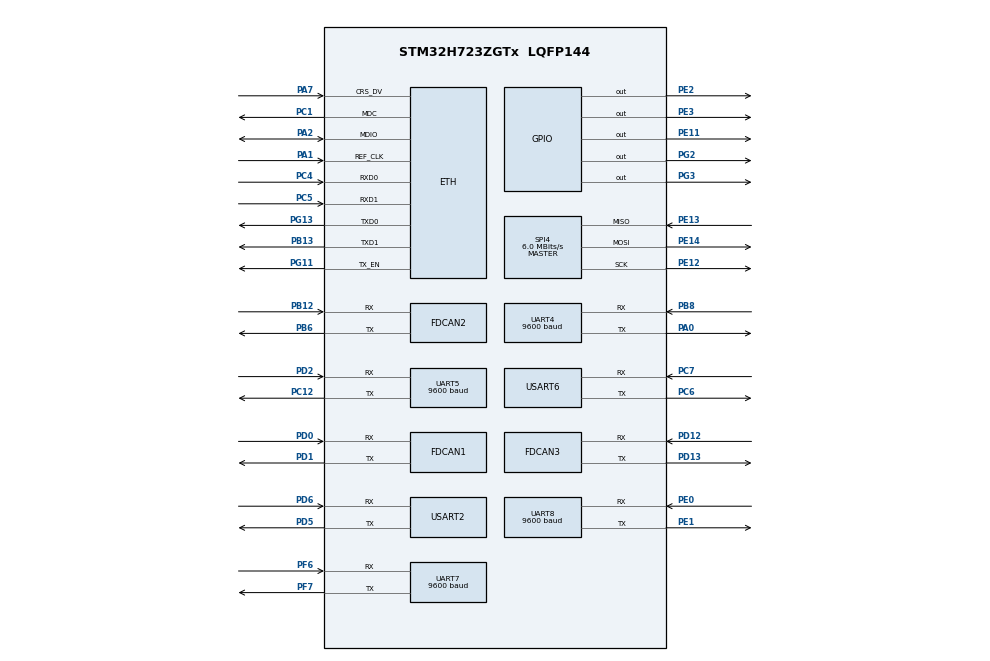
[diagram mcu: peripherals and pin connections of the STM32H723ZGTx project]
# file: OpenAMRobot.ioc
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CORTEX_M7.default_mode_Activation=1
ETH.MediaInterface=HAL_ETH_RMII_MODE
FDCAN1.AutoRetransmission=ENABLE
FDCAN1.CalculateBaudRateNominal=500000
FDCAN1.CalculateTimeBitNominal=2000
FDCAN1.CalculateTimeQuantumNominal=125.0
FDCAN1.NominalPrescaler=6
FDCAN1.NominalTimeSeg1=13
FDCAN1.NominalTimeSeg2=2
FDCAN1.RxFifo0ElmtsNbr=16
FDCAN1.StdFiltersNbr=1
FDCAN1.TxFifoQueueElmtsNbr=8
FDCAN2.AutoRetransmission=ENABLE
FDCAN2.CalculateBaudRateNominal=250000
FDCAN2.CalculateTimeBitNominal=4000
FDCAN2.CalculateTimeQuantumNominal=250.0
FDCAN2.MessageRAMOffset=256
FDCAN2.NominalPrescaler=12
FDCAN2.NominalTimeSeg1=13
FDCAN2.NominalTimeSeg2=2
FDCAN2.RxFifo0ElmtsNbr=16
FDCAN2.StdFiltersNbr=1
FDCAN2.TxFifoQueueElmtsNbr=8
FDCAN3.AutoRetransmission=ENABLE
FDCAN3.CalculateBaudRateNominal=500000
FDCAN3.CalculateTimeBitNominal=2000
FDCAN3.CalculateTimeQuantumNominal=125.0
FDCAN3.MessageRAMOffset=512
FDCAN3.NominalPrescaler=6
FDCAN3.NominalTimeSeg1=13
FDCAN3.NominalTimeSeg2=2
FDCAN3.RxFifo0ElmtsNbr=16
FDCAN3.StdFiltersNbr=1
FDCAN3.TxFifoQueueElmtsNbr=8
Mcu.Family=STM32H7
Mcu.Name=STM32H723ZGTx
Mcu.Package=LQFP144
NVIC.ETH_IRQn=true\:5\:0\:true\:false\:true\:true\:true\:true
NVIC.FDCAN1_IT0_IRQn=true\:5\:0\:true\:false\:true\:true\:true\:true
NVIC.FDCAN2_IT0_IRQn=true\:5\:0\:true\:false\:true\:true\:true\:true
NVIC.FDCAN3_IT0_IRQn=true\:5\:0\:true\:false\:true\:true\:true\:true
NVIC.PriorityGroup=NVIC_PRIORITYGROUP_4
NVIC.UART4_IRQn=true\:5\:0\:true\:false\:true\:true\:true\:true
NVIC.UART5_IRQn=true\:5\:0\:true\:false\:true\:true\:true\:true
NVIC.UART7_IRQn=true\:5\:0\:true\:false\:true\:true\:true\:true
NVIC.UART8_IRQn=true\:5\:0\:true\:false\:true\:true\:true\:true
NVIC.USART2_IRQn=true\:5\:0\:true\:false\:true\:true\:true\:true
NVIC.USART6_IRQn=true\:5\:0\:true\:false\:true\:true\:true\:true
PA0.Mode=Asynchronous
PA0.Signal=UART4_TX
PA1.Mode=RMII
PA1.Signal=ETH_REF_CLK
PA13(JTMS/SWDIO).GPIO_Label=SWDIO
PA13(JTMS/SWDIO).Mode=Serial_Wire
PA13(JTMS/SWDIO).Signal=DEBUG_JTMS-SWDIO
PA14(JTCK/SWCLK).GPIO_Label=SWCLK
PA14(JTCK/SWCLK).Mode=Serial_Wire
PA14(JTCK/SWCLK).Signal=DEBUG_JTCK-SWCLK
PA2.Mode=RMII
PA2.Signal=ETH_MDIO
PA7.Mode=RMII
PA7.Signal=ETH_CRS_DV
PB12.Mode=FDCAN_Activate
PB12.Signal=FDCAN2_RX
PB13.Mode=RMII
PB13.Signal=ETH_TXD1
PB6.Mode=FDCAN_Activate
PB6.Signal=FDCAN2_TX
PB8.Mode=Asynchronous
PB8.Signal=UART4_RX
PC1.Mode=RMII
PC1.Signal=ETH_MDC
PC12.Mode=Asynchronous
PC12.Signal=UART5_TX
PC14-OSC32_IN.Signal=RCC_OSC32_IN
PC15-OSC32_OUT.Signal=RCC_OSC32_OUT
PC4.Mode=RMII
PC4.Signal=ETH_RXD0
PC5.Mode=RMII
PC5.Signal=ETH_RXD1
PC6.Mode=Asynchronous
PC6.Signal=USART6_TX
PC7.Mode=Asynchronous
PC7.Signal=USART6_RX
PD0.Mode=FDCAN_Activate
PD0.Signal=FDCAN1_RX
PD1.Mode=FDCAN_Activate
PD1.Signal=FDCAN1_TX
PD12.Mode=FDCAN_Activate
PD12.Signal=FDCAN3_RX
PD13.Mode=FDCAN_Activate
PD13.Signal=FDCAN3_TX
PD2.Mode=Asynchronous
PD2.Signal=UART5_RX
PD5.Mode=Asynchronous
PD5.Signal=USART2_TX
PD6.Mode=Asynchronous
PD6.Signal=USART2_RX
PE0.Mode=Asynchronous
PE0.Signal=UART8_RX
PE1.Mode=Asynchronous
PE1.Signal=UART8_TX
PE11.PinState=GPIO_PIN_SET
PE11.Signal=GPIO_Output
PE12.Mode=Full_Duplex_Master
PE12.Signal=SPI4_SCK
PE13.GPIO_Mode=GPIO_MODE_AF_PP
PE13.GPIO_PuPd=GPIO_NOPULL
PE13.GPIO_Speed=GPIO_SPEED_FREQ_LOW
PE13.Mode=Full_Duplex_Master
PE13.Signal=SPI4_MISO
PE14.Mode=Full_Duplex_Master
PE14.Signal=SPI4_MOSI
PE2.Signal=GPIO_Output
PE3.Signal=GPIO_Output
PF6.Mode=Asynchronous
PF6.Signal=UART7_RX
PF7.Mode=Asynchronous
PF7.Signal=UART7_TX
PG11.Mode=RMII
PG11.Signal=ETH_TX_EN
PG13.Mode=RMII
PG13.Signal=ETH_TXD0
PG2.Signal=GPIO_Output
PG3.Signal=GPIO_Output
PH0-OSC_IN.Mode=HSE-External-Clock-Source
PH0-OSC_IN.Signal=RCC_OSC_IN
ProjectManager.HeapSize=0x200
ProjectManager.StackSize=0x400
ProjectManager.TargetToolchain=CMake
RCC.ADCFreq_Value=76000000
RCC.APB1Freq_Value=48000000
RCC.APB2Freq_Value=48000000
RCC.APB3Freq_Value=48000000
RCC.APB4Freq_Value=48000000
RCC.CortexFreq_Value=192000000
RCC.D1PPRE=RCC_APB3_DIV2
RCC.D2PPRE1=RCC_APB1_DIV2
RCC.D2PPRE2=RCC_APB2_DIV2
RCC.D3PPRE=RCC_APB4_DIV2
RCC.DIVM1=2
RCC.DIVM2=1
RCC.DIVN1=96
RCC.DIVN2=19
RCC.DIVQ1=8
RCC.HCLKFreq_Value=96000000
RCC.HPRE=RCC_HCLK_DIV2
RCC.HSE_VALUE=8000000
RCC.PLLFRACN=0
RCC.PLLSourceVirtual=RCC_PLLSOURCE_HSE
RCC.SYSCLKFreq_VALUE=192000000
RCC.SYSCLKSource=RCC_SYSCLKSOURCE_PLLCLK
RCC.USBCLockSelection=RCC_USBCLKSOURCE_HSI48
RCC.USBFreq_Value=48000000
SPI4.BaudRatePrescaler=SPI_BAUDRATEPRESCALER_8
SPI4.CalculateBaudRate=6.0 MBits/s
SPI4.DataSize=SPI_DATASIZE_8BIT
SPI4.Direction=SPI_DIRECTION_2LINES
SPI4.Mode=SPI_MODE_MASTER
SPI4.VirtualType=VM_MASTER
UART4.BaudRate=9600
UART4.Mode=MODE_RX
UART4.RxPinLevelInvertParam=UART_ADVFEATURE_RXINV_ENABLE
UART5.BaudRate=9600
UART5.Mode=MODE_RX
UART5.RxPinLevelInvertParam=UART_ADVFEATURE_RXINV_ENABLE
UART7.BaudRate=9600
UART7.Mode=MODE_RX
UART7.RxPinLevelInvertParam=UART_ADVFEATURE_RXINV_ENABLE
UART8.BaudRate=9600
UART8.Mode=MODE_RX
UART8.RxPinLevelInvertParam=UART_ADVFEATURE_RXINV_ENABLE
USART2.VirtualMode-Asynchronous=VM_ASYNC
USART6.VirtualMode-Asynchronous=VM_ASYNC
VP_MEMORYMAP_VS_MEMORYMAP.Mode=CurAppReg
VP_NUCLEO-H723ZG_VS_BSP_COMMON.Mode=COMMON
board=NUCLEO-H723ZG

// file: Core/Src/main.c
/* USER CODE BEGIN Header */
/**
  ******************************************************************************
  * @file           : main.c
  * @brief          : Main program body
  ******************************************************************************
  * @attention
  *
  * Copyright (c) 2026 STMicroelectronics.
  * All rights reserved.
  *
  * This software is licensed under terms that can be found in the LICENSE file
  * in the root directory of this software component.
  * If no LICENSE file comes with this software, it is provided AS-IS.
  *
  ******************************************************************************
  */
/* USER CODE END Header */
#include "main.h"
#include "string.h"

#if defined ( __ICCARM__ ) /*!< IAR Compiler */
#pragma location=0x30000000
ETH_DMADescTypeDef  DMARxDscrTab[ETH_RX_DESC_CNT]; /* Ethernet Rx DMA Descriptors */
#pragma location=0x30000080
ETH_DMADescTypeDef  DMATxDscrTab[ETH_TX_DESC_CNT]; /* Ethernet Tx DMA Descriptors */

#elif defined ( __CC_ARM )  /* MDK ARM Compiler */

__attribute__((at(0x30000000))) ETH_DMADescTypeDef  DMARxDscrTab[ETH_RX_DESC_CNT]; /* Ethernet Rx DMA Descriptors */
__attribute__((at(0x30000080))) ETH_DMADescTypeDef  DMATxDscrTab[ETH_TX_DESC_CNT]; /* Ethernet Tx DMA Descriptors */

#elif defined ( __GNUC__ ) /* GNU Compiler */

ETH_DMADescTypeDef DMARxDscrTab[ETH_RX_DESC_CNT] __attribute__((section(".RxDescripSection"))); /* Ethernet Rx DMA Descriptors */
ETH_DMADescTypeDef DMATxDscrTab[ETH_TX_DESC_CNT] __attribute__((section(".TxDescripSection")));   /* Ethernet Tx DMA Descriptors */
#endif

ETH_TxPacketConfig TxConfig;

ETH_HandleTypeDef heth;

FDCAN_HandleTypeDef hfdcan1;
FDCAN_HandleTypeDef hfdcan2;
FDCAN_HandleTypeDef hfdcan3;

SPI_HandleTypeDef hspi4;

UART_HandleTypeDef huart4;
UART_HandleTypeDef huart5;
UART_HandleTypeDef huart7;
UART_HandleTypeDef huart8;
UART_HandleTypeDef huart2;
UART_HandleTypeDef huart6;

void SystemClock_Config(void);
static void MPU_Config(void);
static void MX_GPIO_Init(void);
static void MX_FDCAN1_Init(void);
static void MX_FDCAN2_Init(void);
static void MX_FDCAN3_Init(void);
static void MX_SPI4_Init(void);
static void MX_UART7_Init(void);
static void MX_USART2_UART_Init(void);
static void MX_USART6_UART_Init(void);
static void MX_ETH_Init(void);
static void MX_UART8_Init(void);
static void MX_UART4_Init(void);
static void MX_UART5_Init(void);

int main(void)
{

  /* MPU Configuration--------------------------------------------------------*/
  MPU_Config();

  /* MCU Configuration--------------------------------------------------------*/

  /* Reset of all peripherals, Initializes the Flash interface and the Systick. */
  HAL_Init();

  /* Configure the system clock */
  SystemClock_Config();

  /* Initialize all configured peripherals */
  MX_GPIO_Init();
  MX_FDCAN1_Init();
  MX_FDCAN2_Init();
  MX_FDCAN3_Init();
  MX_SPI4_Init();
  MX_UART7_Init();
  MX_USART2_UART_Init();
  MX_USART6_UART_Init();
  MX_ETH_Init();
  MX_UART8_Init();
  MX_UART4_Init();
  MX_UART5_Init();
  /* USER CODE BEGIN 2 */

  /*
   * Pin-map exceptions (NUCLEO-H723ZG pin map, Section 7):
   * PA0, PC12 and PF7 are unused MCU UART TX pins for the
   * receive-only MB7060 interfaces.
   * PE1 is released from UART8_TX and repurposed as the
   * onboard LD2 debug GPIO.
  */
  HAL_GPIO_DeInit(GPIOA, GPIO_PIN_0);
  HAL_GPIO_DeInit(GPIOC, GPIO_PIN_12);
  HAL_GPIO_DeInit(GPIOF, GPIO_PIN_7);
  HAL_GPIO_DeInit(GPIOE, GPIO_PIN_1);

  /* Repurpose LD2 (PE1) from UART8_TX as a debug GPIO. */
  GPIO_InitTypeDef GPIO_InitStruct = {0};
  HAL_GPIO_WritePin(GPIOE, GPIO_PIN_1, GPIO_PIN_RESET);
  GPIO_InitStruct.Pin = GPIO_PIN_1;
  GPIO_InitStruct.Mode = GPIO_MODE_OUTPUT_PP;
  GPIO_InitStruct.Pull = GPIO_NOPULL;
  GPIO_InitStruct.Speed = GPIO_SPEED_FREQ_LOW;
  HAL_GPIO_Init(GPIOE, &GPIO_InitStruct);

  /* USER CODE END 2 */

  /* Infinite loop */
  while (1)
  {

  }
}

void SystemClock_Config(void)
{
  RCC_OscInitTypeDef RCC_OscInitStruct = {0};
  RCC_ClkInitTypeDef RCC_ClkInitStruct = {0};

  /** Supply configuration update enable
  */
  HAL_PWREx_ConfigSupply(PWR_LDO_SUPPLY);

  /** Configure the main internal regulator output voltage
  */
  __HAL_PWR_VOLTAGESCALING_CONFIG(PWR_REGULATOR_VOLTAGE_SCALE2);

  while(!__HAL_PWR_GET_FLAG(PWR_FLAG_VOSRDY)) {}

  /** Initializes the RCC Oscillators according to the specified parameters
  * in the RCC_OscInitTypeDef structure.
  */
  RCC_OscInitStruct.OscillatorType = RCC_OSCILLATORTYPE_HSE;
  RCC_OscInitStruct.HSEState = RCC_HSE_BYPASS;
  RCC_OscInitStruct.PLL.PLLState = RCC_PLL_ON;
  RCC_OscInitStruct.PLL.PLLSource = RCC_PLLSOURCE_HSE;
  RCC_OscInitStruct.PLL.PLLM = 2;
  RCC_OscInitStruct.PLL.PLLN = 96;
  RCC_OscInitStruct.PLL.PLLP = 2;
  RCC_OscInitStruct.PLL.PLLQ = 8;
  RCC_OscInitStruct.PLL.PLLR = 2;
  RCC_OscInitStruct.PLL.PLLRGE = RCC_PLL1VCIRANGE_2;
  RCC_OscInitStruct.PLL.PLLVCOSEL = RCC_PLL1VCOWIDE;
  RCC_OscInitStruct.PLL.PLLFRACN = 0;
  if (HAL_RCC_OscConfig(&RCC_OscInitStruct) != HAL_OK)
  {
    Error_Handler();
  }

  /** Initializes the CPU, AHB and APB buses clocks
  */
  RCC_ClkInitStruct.ClockType = RCC_CLOCKTYPE_HCLK|RCC_CLOCKTYPE_SYSCLK
                              |RCC_CLOCKTYPE_PCLK1|RCC_CLOCKTYPE_PCLK2
                              |RCC_CLOCKTYPE_D3PCLK1|RCC_CLOCKTYPE_D1PCLK1;
  RCC_ClkInitStruct.SYSCLKSource = RCC_SYSCLKSOURCE_PLLCLK;
  RCC_ClkInitStruct.SYSCLKDivider = RCC_SYSCLK_DIV1;
  RCC_ClkInitStruct.AHBCLKDivider = RCC_HCLK_DIV2;
  RCC_ClkInitStruct.APB3CLKDivider = RCC_APB3_DIV2;
  RCC_ClkInitStruct.APB1CLKDivider = RCC_APB1_DIV2;
  RCC_ClkInitStruct.APB2CLKDivider = RCC_APB2_DIV2;
  RCC_ClkInitStruct.APB4CLKDivider = RCC_APB4_DIV2;

  if (HAL_RCC_ClockConfig(&RCC_ClkInitStruct, FLASH_LATENCY_1) != HAL_OK)
  {
    Error_Handler();
  }
}

static void MX_ETH_Init(void)
{

   static uint8_t MACAddr[6];

  heth.Instance = ETH;
  MACAddr[0] = 0x00;
  MACAddr[1] = 0x80;
  MACAddr[2] = 0xE1;
  MACAddr[3] = 0x00;
  MACAddr[4] = 0x00;
  MACAddr[5] = 0x00;
  heth.Init.MACAddr = &MACAddr[0];
  heth.Init.MediaInterface = HAL_ETH_RMII_MODE;
  heth.Init.TxDesc = DMATxDscrTab;
  heth.Init.RxDesc = DMARxDscrTab;
  heth.Init.RxBuffLen = 1536;

  if (HAL_ETH_Init(&heth) != HAL_OK)
  {
    Error_Handler();
  }

  memset(&TxConfig, 0 , sizeof(ETH_TxPacketConfig));
  TxConfig.Attributes = ETH_TX_PACKETS_FEATURES_CSUM | ETH_TX_PACKETS_FEATURES_CRCPAD;
  TxConfig.ChecksumCtrl = ETH_CHECKSUM_IPHDR_PAYLOAD_INSERT_PHDR_CALC;
  TxConfig.CRCPadCtrl = ETH_CRC_PAD_INSERT;

}

static void MX_FDCAN1_Init(void)
{

  hfdcan1.Instance = FDCAN1;
  hfdcan1.Init.FrameFormat = FDCAN_FRAME_CLASSIC;
  hfdcan1.Init.Mode = FDCAN_MODE_NORMAL;
  hfdcan1.Init.AutoRetransmission = ENABLE;
  hfdcan1.Init.TransmitPause = DISABLE;
  hfdcan1.Init.ProtocolException = DISABLE;
  hfdcan1.Init.NominalPrescaler = 6;
  hfdcan1.Init.NominalSyncJumpWidth = 1;
  hfdcan1.Init.NominalTimeSeg1 = 13;
  hfdcan1.Init.NominalTimeSeg2 = 2;
  hfdcan1.Init.DataPrescaler = 1;
  hfdcan1.Init.DataSyncJumpWidth = 1;
  hfdcan1.Init.DataTimeSeg1 = 1;
  hfdcan1.Init.DataTimeSeg2 = 1;
  hfdcan1.Init.MessageRAMOffset = 0;
  hfdcan1.Init.StdFiltersNbr = 1;
  hfdcan1.Init.ExtFiltersNbr = 0;
  hfdcan1.Init.RxFifo0ElmtsNbr = 16;
  hfdcan1.Init.RxFifo0ElmtSize = FDCAN_DATA_BYTES_8;
  hfdcan1.Init.RxFifo1ElmtsNbr = 0;
  hfdcan1.Init.RxFifo1ElmtSize = FDCAN_DATA_BYTES_8;
  hfdcan1.Init.RxBuffersNbr = 0;
  hfdcan1.Init.RxBufferSize = FDCAN_DATA_BYTES_8;
  hfdcan1.Init.TxEventsNbr = 0;
  hfdcan1.Init.TxBuffersNbr = 0;
  hfdcan1.Init.TxFifoQueueElmtsNbr = 8;
  hfdcan1.Init.TxFifoQueueMode = FDCAN_TX_FIFO_OPERATION;
  hfdcan1.Init.TxElmtSize = FDCAN_DATA_BYTES_8;
  if (HAL_FDCAN_Init(&hfdcan1) != HAL_OK)
  {
    Error_Handler();
  }

}

static void MX_FDCAN2_Init(void)
{

  hfdcan2.Instance = FDCAN2;
  hfdcan2.Init.FrameFormat = FDCAN_FRAME_CLASSIC;
  hfdcan2.Init.Mode = FDCAN_MODE_NORMAL;
  hfdcan2.Init.AutoRetransmission = ENABLE;
  hfdcan2.Init.TransmitPause = DISABLE;
  hfdcan2.Init.ProtocolException = DISABLE;
  hfdcan2.Init.NominalPrescaler = 12;
  hfdcan2.Init.NominalSyncJumpWidth = 1;
  hfdcan2.Init.NominalTimeSeg1 = 13;
  hfdcan2.Init.NominalTimeSeg2 = 2;
  hfdcan2.Init.DataPrescaler = 1;
  hfdcan2.Init.DataSyncJumpWidth = 1;
  hfdcan2.Init.DataTimeSeg1 = 1;
  hfdcan2.Init.DataTimeSeg2 = 1;
  hfdcan2.Init.MessageRAMOffset = 256;
  hfdcan2.Init.StdFiltersNbr = 1;
  hfdcan2.Init.ExtFiltersNbr = 0;
  hfdcan2.Init.RxFifo0ElmtsNbr = 16;
  hfdcan2.Init.RxFifo0ElmtSize = FDCAN_DATA_BYTES_8;
  hfdcan2.Init.RxFifo1ElmtsNbr = 0;
  hfdcan2.Init.RxFifo1ElmtSize = FDCAN_DATA_BYTES_8;
  hfdcan2.Init.RxBuffersNbr = 0;
  hfdcan2.Init.RxBufferSize = FDCAN_DATA_BYTES_8;
  hfdcan2.Init.TxEventsNbr = 0;
  hfdcan2.Init.TxBuffersNbr = 0;
  hfdcan2.Init.TxFifoQueueElmtsNbr = 8;
  hfdcan2.Init.TxFifoQueueMode = FDCAN_TX_FIFO_OPERATION;
  hfdcan2.Init.TxElmtSize = FDCAN_DATA_BYTES_8;
  if (HAL_FDCAN_Init(&hfdcan2) != HAL_OK)
  {
    Error_Handler();
  }

}

static void MX_FDCAN3_Init(void)
{

  hfdcan3.Instance = FDCAN3;
  hfdcan3.Init.FrameFormat = FDCAN_FRAME_CLASSIC;
  hfdcan3.Init.Mode = FDCAN_MODE_NORMAL;
  hfdcan3.Init.AutoRetransmission = ENABLE;
  hfdcan3.Init.TransmitPause = DISABLE;
  hfdcan3.Init.ProtocolException = DISABLE;
  hfdcan3.Init.NominalPrescaler = 6;
  hfdcan3.Init.NominalSyncJumpWidth = 1;
  hfdcan3.Init.NominalTimeSeg1 = 13;
  hfdcan3.Init.NominalTimeSeg2 = 2;
  hfdcan3.Init.DataPrescaler = 1;
  hfdcan3.Init.DataSyncJumpWidth = 1;
  hfdcan3.Init.DataTimeSeg1 = 1;
  hfdcan3.Init.DataTimeSeg2 = 1;
  hfdcan3.Init.MessageRAMOffset = 512;
  hfdcan3.Init.StdFiltersNbr = 1;
  hfdcan3.Init.ExtFiltersNbr = 0;
  hfdcan3.Init.RxFifo0ElmtsNbr = 16;
  hfdcan3.Init.RxFifo0ElmtSize = FDCAN_DATA_BYTES_8;
  hfdcan3.Init.RxFifo1ElmtsNbr = 0;
  hfdcan3.Init.RxFifo1ElmtSize = FDCAN_DATA_BYTES_8;
  hfdcan3.Init.RxBuffersNbr = 0;
  hfdcan3.Init.RxBufferSize = FDCAN_DATA_BYTES_8;
  hfdcan3.Init.TxEventsNbr = 0;
  hfdcan3.Init.TxBuffersNbr = 0;
  hfdcan3.Init.TxFifoQueueElmtsNbr = 8;
  hfdcan3.Init.TxFifoQueueMode = FDCAN_TX_FIFO_OPERATION;
  hfdcan3.Init.TxElmtSize = FDCAN_DATA_BYTES_8;
  if (HAL_FDCAN_Init(&hfdcan3) != HAL_OK)
  {
    Error_Handler();
  }

}

static void MX_SPI4_Init(void)
{

  /* SPI4 parameter configuration*/
  hspi4.Instance = SPI4;
  hspi4.Init.Mode = SPI_MODE_MASTER;
  hspi4.Init.Direction = SPI_DIRECTION_2LINES;
  hspi4.Init.DataSize = SPI_DATASIZE_8BIT;
  hspi4.Init.CLKPolarity = SPI_POLARITY_LOW;
  hspi4.Init.CLKPhase = SPI_PHASE_1EDGE;
  hspi4.Init.NSS = SPI_NSS_SOFT;
  hspi4.Init.BaudRatePrescaler = SPI_BAUDRATEPRESCALER_8;
  hspi4.Init.FirstBit = SPI_FIRSTBIT_MSB;
  hspi4.Init.TIMode = SPI_TIMODE_DISABLE;
  hspi4.Init.CRCCalculation = SPI_CRCCALCULATION_DISABLE;
  hspi4.Init.CRCPolynomial = 0x0;
  hspi4.Init.NSSPMode = SPI_NSS_PULSE_ENABLE;
  hspi4.Init.NSSPolarity = SPI_NSS_POLARITY_LOW;
  hspi4.Init.FifoThreshold = SPI_FIFO_THRESHOLD_01DATA;
  hspi4.Init.TxCRCInitializationPattern = SPI_CRC_INITIALIZATION_ALL_ZERO_PATTERN;
  hspi4.Init.RxCRCInitializationPattern = SPI_CRC_INITIALIZATION_ALL_ZERO_PATTERN;
  hspi4.Init.MasterSSIdleness = SPI_MASTER_SS_IDLENESS_00CYCLE;
  hspi4.Init.MasterInterDataIdleness = SPI_MASTER_INTERDATA_IDLENESS_00CYCLE;
  hspi4.Init.MasterReceiverAutoSusp = SPI_MASTER_RX_AUTOSUSP_DISABLE;
  hspi4.Init.MasterKeepIOState = SPI_MASTER_KEEP_IO_STATE_DISABLE;
  hspi4.Init.IOSwap = SPI_IO_SWAP_DISABLE;
  if (HAL_SPI_Init(&hspi4) != HAL_OK)
  {
    Error_Handler();
  }

}

static void MX_UART4_Init(void)
{

  huart4.Instance = UART4;
  huart4.Init.BaudRate = 9600;
  huart4.Init.WordLength = UART_WORDLENGTH_8B;
  huart4.Init.StopBits = UART_STOPBITS_1;
  huart4.Init.Parity = UART_PARITY_NONE;
  huart4.Init.Mode = UART_MODE_RX;
  huart4.Init.HwFlowCtl = UART_HWCONTROL_NONE;
  huart4.Init.OverSampling = UART_OVERSAMPLING_16;
  huart4.Init.OneBitSampling = UART_ONE_BIT_SAMPLE_DISABLE;
  huart4.Init.ClockPrescaler = UART_PRESCALER_DIV1;
  huart4.AdvancedInit.AdvFeatureInit = UART_ADVFEATURE_RXINVERT_INIT;
  huart4.AdvancedInit.RxPinLevelInvert = UART_ADVFEATURE_RXINV_ENABLE;
  if (HAL_UART_Init(&huart4) != HAL_OK)
  {
    Error_Handler();
  }
  if (HAL_UARTEx_SetTxFifoThreshold(&huart4, UART_TXFIFO_THRESHOLD_1_8) != HAL_OK)
  {
    Error_Handler();
  }
  if (HAL_UARTEx_SetRxFifoThreshold(&huart4, UART_RXFIFO_THRESHOLD_1_8) != HAL_OK)
  {
    Error_Handler();
  }
  if (HAL_UARTEx_DisableFifoMode(&huart4) != HAL_OK)
  {
    Error_Handler();
  }

}

static void MX_UART5_Init(void)
{

  huart5.Instance = UART5;
  huart5.Init.BaudRate = 9600;
  huart5.Init.WordLength = UART_WORDLENGTH_8B;
  huart5.Init.StopBits = UART_STOPBITS_1;
  huart5.Init.Parity = UART_PARITY_NONE;
  huart5.Init.Mode = UART_MODE_RX;
  huart5.Init.HwFlowCtl = UART_HWCONTROL_NONE;
  huart5.Init.OverSampling = UART_OVERSAMPLING_16;
  huart5.Init.OneBitSampling = UART_ONE_BIT_SAMPLE_DISABLE;
  huart5.Init.ClockPrescaler = UART_PRESCALER_DIV1;
  huart5.AdvancedInit.AdvFeatureInit = UART_ADVFEATURE_RXINVERT_INIT;
  huart5.AdvancedInit.RxPinLevelInvert = UART_ADVFEATURE_RXINV_ENABLE;
  if (HAL_UART_Init(&huart5) != HAL_OK)
  {
    Error_Handler();
  }
  if (HAL_UARTEx_SetTxFifoThreshold(&huart5, UART_TXFIFO_THRESHOLD_1_8) != HAL_OK)
  {
    Error_Handler();
  }
  if (HAL_UARTEx_SetRxFifoThreshold(&huart5, UART_RXFIFO_THRESHOLD_1_8) != HAL_OK)
  {
    Error_Handler();
  }
  if (HAL_UARTEx_DisableFifoMode(&huart5) != HAL_OK)
  {
    Error_Handler();
  }

}

static void MX_UART7_Init(void)
{

  huart7.Instance = UART7;
  huart7.Init.BaudRate = 9600;
  huart7.Init.WordLength = UART_WORDLENGTH_8B;
  huart7.Init.StopBits = UART_STOPBITS_1;
  huart7.Init.Parity = UART_PARITY_NONE;
  huart7.Init.Mode = UART_MODE_RX;
  huart7.Init.HwFlowCtl = UART_HWCONTROL_NONE;
  huart7.Init.OverSampling = UART_OVERSAMPLING_16;
  huart7.Init.OneBitSampling = UART_ONE_BIT_SAMPLE_DISABLE;
  huart7.Init.ClockPrescaler = UART_PRESCALER_DIV1;
  huart7.AdvancedInit.AdvFeatureInit = UART_ADVFEATURE_RXINVERT_INIT;
  huart7.AdvancedInit.RxPinLevelInvert = UART_ADVFEATURE_RXINV_ENABLE;
  if (HAL_UART_Init(&huart7) != HAL_OK)
  {
    Error_Handler();
  }
  if (HAL_UARTEx_SetTxFifoThreshold(&huart7, UART_TXFIFO_THRESHOLD_1_8) != HAL_OK)
  {
    Error_Handler();
  }
  if (HAL_UARTEx_SetRxFifoThreshold(&huart7, UART_RXFIFO_THRESHOLD_1_8) != HAL_OK)
  {
    Error_Handler();
  }
  if (HAL_UARTEx_DisableFifoMode(&huart7) != HAL_OK)
  {
    Error_Handler();
  }

}

static void MX_UART8_Init(void)
{

  huart8.Instance = UART8;
  huart8.Init.BaudRate = 9600;
  huart8.Init.WordLength = UART_WORDLENGTH_8B;
  huart8.Init.StopBits = UART_STOPBITS_1;
  huart8.Init.Parity = UART_PARITY_NONE;
  huart8.Init.Mode = UART_MODE_RX;
  huart8.Init.HwFlowCtl = UART_HWCONTROL_NONE;
  huart8.Init.OverSampling = UART_OVERSAMPLING_16;
  huart8.Init.OneBitSampling = UART_ONE_BIT_SAMPLE_DISABLE;
  huart8.Init.ClockPrescaler = UART_PRESCALER_DIV1;
  huart8.AdvancedInit.AdvFeatureInit = UART_ADVFEATURE_RXINVERT_INIT;
  huart8.AdvancedInit.RxPinLevelInvert = UART_ADVFEATURE_RXINV_ENABLE;
  if (HAL_UART_Init(&huart8) != HAL_OK)
  {
    Error_Handler();
  }
  if (HAL_UARTEx_SetTxFifoThreshold(&huart8, UART_TXFIFO_THRESHOLD_1_8) != HAL_OK)
  {
    Error_Handler();
  }
  if (HAL_UARTEx_SetRxFifoThreshold(&huart8, UART_RXFIFO_THRESHOLD_1_8) != HAL_OK)
  {
    Error_Handler();
  }
  if (HAL_UARTEx_DisableFifoMode(&huart8) != HAL_OK)
  {
    Error_Handler();
  }

}

static void MX_USART2_UART_Init(void)
{

  huart2.Instance = USART2;
  huart2.Init.BaudRate = 115200;
  huart2.Init.WordLength = UART_WORDLENGTH_8B;
  huart2.Init.StopBits = UART_STOPBITS_1;
  huart2.Init.Parity = UART_PARITY_NONE;
  huart2.Init.Mode = UART_MODE_TX_RX;
  huart2.Init.HwFlowCtl = UART_HWCONTROL_NONE;
  huart2.Init.OverSampling = UART_OVERSAMPLING_16;
  huart2.Init.OneBitSampling = UART_ONE_BIT_SAMPLE_DISABLE;
  huart2.Init.ClockPrescaler = UART_PRESCALER_DIV1;
  huart2.AdvancedInit.AdvFeatureInit = UART_ADVFEATURE_NO_INIT;
  if (HAL_UART_Init(&huart2) != HAL_OK)
  {
    Error_Handler();
  }
  if (HAL_UARTEx_SetTxFifoThreshold(&huart2, UART_TXFIFO_THRESHOLD_1_8) != HAL_OK)
  {
    Error_Handler();
  }
  if (HAL_UARTEx_SetRxFifoThreshold(&huart2, UART_RXFIFO_THRESHOLD_1_8) != HAL_OK)
  {
    Error_Handler();
  }
  if (HAL_UARTEx_DisableFifoMode(&huart2) != HAL_OK)
  {
    Error_Handler();
  }

}

static void MX_USART6_UART_Init(void)
{

  huart6.Instance = USART6;
  huart6.Init.BaudRate = 115200;
  huart6.Init.WordLength = UART_WORDLENGTH_8B;
  huart6.Init.StopBits = UART_STOPBITS_1;
  huart6.Init.Parity = UART_PARITY_NONE;
  huart6.Init.Mode = UART_MODE_TX_RX;
  huart6.Init.HwFlowCtl = UART_HWCONTROL_NONE;
  huart6.Init.OverSampling = UART_OVERSAMPLING_16;
  huart6.Init.OneBitSampling = UART_ONE_BIT_SAMPLE_DISABLE;
  huart6.Init.ClockPrescaler = UART_PRESCALER_DIV1;
  huart6.AdvancedInit.AdvFeatureInit = UART_ADVFEATURE_NO_INIT;
  if (HAL_UART_Init(&huart6) != HAL_OK)
  {
    Error_Handler();
  }
  if (HAL_UARTEx_SetTxFifoThreshold(&huart6, UART_TXFIFO_THRESHOLD_1_8) != HAL_OK)
  {
    Error_Handler();
  }
  if (HAL_UARTEx_SetRxFifoThreshold(&huart6, UART_RXFIFO_THRESHOLD_1_8) != HAL_OK)
  {
    Error_Handler();
  }
  if (HAL_UARTEx_DisableFifoMode(&huart6) != HAL_OK)
  {
    Error_Handler();
  }

}

static void MX_GPIO_Init(void)
{
  GPIO_InitTypeDef GPIO_InitStruct = {0};

  /* GPIO Ports Clock Enable */
  __HAL_RCC_GPIOE_CLK_ENABLE();
  __HAL_RCC_GPIOC_CLK_ENABLE();
  __HAL_RCC_GPIOF_CLK_ENABLE();
  __HAL_RCC_GPIOH_CLK_ENABLE();
  __HAL_RCC_GPIOA_CLK_ENABLE();
  __HAL_RCC_GPIOB_CLK_ENABLE();
  __HAL_RCC_GPIOD_CLK_ENABLE();
  __HAL_RCC_GPIOG_CLK_ENABLE();

  /*Configure GPIO pin Output Level */
  HAL_GPIO_WritePin(GPIOE, GPIO_PIN_2|GPIO_PIN_3, GPIO_PIN_RESET);

  /*Configure GPIO pin Output Level */
  HAL_GPIO_WritePin(GPIOE, GPIO_PIN_11, GPIO_PIN_SET);

  /*Configure GPIO pin Output Level */
  HAL_GPIO_WritePin(GPIOG, GPIO_PIN_2|GPIO_PIN_3, GPIO_PIN_RESET);

  /*Configure GPIO pins : PE2 PE3 PE11 */
  GPIO_InitStruct.Pin = GPIO_PIN_2|GPIO_PIN_3|GPIO_PIN_11;
  GPIO_InitStruct.Mode = GPIO_MODE_OUTPUT_PP;
  GPIO_InitStruct.Pull = GPIO_NOPULL;
  GPIO_InitStruct.Speed = GPIO_SPEED_FREQ_LOW;
  HAL_GPIO_Init(GPIOE, &GPIO_InitStruct);

  /*Configure GPIO pins : PG2 PG3 */
  GPIO_InitStruct.Pin = GPIO_PIN_2|GPIO_PIN_3;
  GPIO_InitStruct.Mode = GPIO_MODE_OUTPUT_PP;
  GPIO_InitStruct.Pull = GPIO_NOPULL;
  GPIO_InitStruct.Speed = GPIO_SPEED_FREQ_LOW;
  HAL_GPIO_Init(GPIOG, &GPIO_InitStruct);

}

 /* MPU Configuration */

void MPU_Config(void)
{
  MPU_Region_InitTypeDef MPU_InitStruct = {0};

  /* Disables the MPU */
  HAL_MPU_Disable();

  /** Initializes and configures the Region and the memory to be protected
  */
  MPU_InitStruct.Enable = MPU_REGION_ENABLE;
  MPU_InitStruct.Number = MPU_REGION_NUMBER0;
  MPU_InitStruct.BaseAddress = 0x0;
  MPU_InitStruct.Size = MPU_REGION_SIZE_4GB;
  MPU_InitStruct.SubRegionDisable = 0x87;
  MPU_InitStruct.TypeExtField = MPU_TEX_LEVEL0;
  MPU_InitStruct.AccessPermission = MPU_REGION_NO_ACCESS;
  MPU_InitStruct.DisableExec = MPU_INSTRUCTION_ACCESS_DISABLE;
  MPU_InitStruct.IsShareable = MPU_ACCESS_SHAREABLE;
  MPU_InitStruct.IsCacheable = MPU_ACCESS_NOT_CACHEABLE;
  MPU_InitStruct.IsBufferable = MPU_ACCESS_NOT_BUFFERABLE;

  HAL_MPU_ConfigRegion(&MPU_InitStruct);
  /* Enables the MPU */
  HAL_MPU_Enable(MPU_PRIVILEGED_DEFAULT);

}

void Error_Handler(void)
{
  __disable_irq();
  while (1)
  {
  }
}
